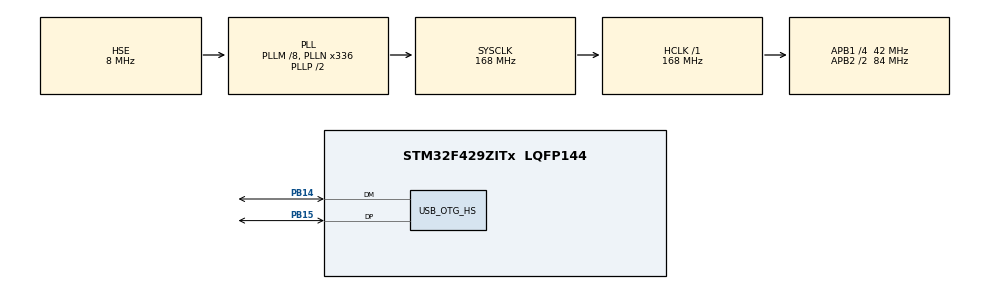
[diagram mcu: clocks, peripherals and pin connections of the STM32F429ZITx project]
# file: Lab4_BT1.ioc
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Mcu.Family=STM32F4
Mcu.Name=STM32F429ZITx
Mcu.Package=LQFP144
NVIC.OTG_HS_IRQn=true\:0\:0\:false\:false\:true\:true\:true\:true
NVIC.PriorityGroup=NVIC_PRIORITYGROUP_4
PA13.Mode=Serial_Wire
PA13.Signal=SYS_JTMS-SWDIO
PA14.Mode=Serial_Wire
PA14.Signal=SYS_JTCK-SWCLK
PB14.Mode=Device_Only_FS
PB14.Signal=USB_OTG_HS_DM
PB15.Mode=Device_Only_FS
PB15.Signal=USB_OTG_HS_DP
PH0/OSC_IN.Mode=HSE-External-Oscillator
PH0/OSC_IN.Signal=RCC_OSC_IN
PH1/OSC_OUT.Mode=HSE-External-Oscillator
PH1/OSC_OUT.Signal=RCC_OSC_OUT
ProjectManager.HeapSize=0x2000
ProjectManager.StackSize=0x400
ProjectManager.TargetToolchain=STM32CubeIDE
RCC.48MHZClocksFreq_Value=48000000
RCC.AHBFreq_Value=168000000
RCC.APB1CLKDivider=RCC_HCLK_DIV4
RCC.APB1Freq_Value=42000000
RCC.APB1TimFreq_Value=84000000
RCC.APB2CLKDivider=RCC_HCLK_DIV2
RCC.APB2Freq_Value=84000000
RCC.APB2TimFreq_Value=168000000
RCC.CortexFreq_Value=168000000
RCC.HCLKFreq_Value=168000000
RCC.HSE_VALUE=8000000
RCC.HSI_VALUE=16000000
RCC.LSE_VALUE=32768
RCC.PLLM=8
RCC.PLLN=336
RCC.PLLQ=7
RCC.SYSCLKFreq_VALUE=168000000
RCC.SYSCLKSource=RCC_SYSCLKSOURCE_PLLCLK
RCC.VCOOutputFreq_Value=336000000
USB_DEVICE.CLASS_NAME_HS=CDC
USB_DEVICE.VirtualMode-CDC_HS=Cdc
USB_DEVICE.VirtualModeHS=Cdc_HS
USB_OTG_HS.VirtualMode-Device_Only_FS=Device_Only_FS
VP_USB_DEVICE_VS_USB_DEVICE_CDC_HS.Mode=CDC_HS
board=custom

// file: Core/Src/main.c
/* USER CODE BEGIN Header */
/**
  ******************************************************************************
  * @file           : main.c
  * @brief          : Main program body
  ******************************************************************************
  * @attention
  *
  * Copyright (c) 2022 STMicroelectronics.
  * All rights reserved.
  *
  * This software is licensed under terms that can be found in the LICENSE file
  * in the root directory of this software component.
  * If no LICENSE file comes with this software, it is provided AS-IS.
  *
  ******************************************************************************
  */
/* USER CODE END Header */
#include "main.h"
#include "usb_device.h"
#include "usbd_cdc_if.h"
#include "stm32f429i_discovery_lcd.h"
#include "stm32f429i_discovery_gyroscope.h"

void SystemClock_Config(void);
static void MX_GPIO_Init(void);

int main(void)
{
  /* USER CODE BEGIN 1 */
	float DATA[3];
	char X[10], Y[10], Z[10];
  /* USER CODE END 1 */

  /* MCU Configuration--------------------------------------------------------*/

  /* Reset of all peripherals, Initializes the Flash interface and the Systick. */
  HAL_Init();

  /* Configure the system clock */
  SystemClock_Config();

  /* Initialize all configured peripherals */
  BSP_GYRO_Init();
  BSP_SDRAM_Init();
  MX_GPIO_Init();
  MX_USB_DEVICE_Init();
    /* USER CODE BEGIN 2 */
  BSP_LCD_Init();//init LCD
    //set the layer buffer address into SDRAM
  BSP_LCD_LayerDefaultInit(1, SDRAM_DEVICE_ADDR);
  BSP_LCD_SelectLayer(1);//select on which layer we write
  BSP_LCD_DisplayOn();//turn on LCD
  BSP_LCD_Clear(LCD_COLOR_BLUE);//clear the LCD on blue color
  BSP_LCD_SetBackColor(LCD_COLOR_BLUE);//set text background color
  BSP_LCD_SetTextColor(LCD_COLOR_WHITE);//set text color
    //write text
  /* USER CODE BEGIN 2 */

  /* USER CODE END 2 */

  /* Infinite loop */
  while (1)
  {
	  L3GD20_ReadXYZAngRate(&DATA);

	  if (DATA[0] < -10){
		  BSP_LCD_DisplayStringAtLine(0, (uint8_t*)"       ^");
	  	  BSP_LCD_DisplayStringAtLine(10, (uint8_t*)"        ");
	  }
	  else if (DATA[0] > 10){
		  BSP_LCD_DisplayStringAtLine(10, (uint8_t*)"       v");
	  	  BSP_LCD_DisplayStringAtLine(0, (uint8_t*)"        ");
	  }
	  else{
		  BSP_LCD_DisplayStringAtLine(0, (uint8_t*)"        ");
		  BSP_LCD_DisplayStringAtLine(10, (uint8_t*)"        ");
	  }

	  if (DATA[1] > 10)
		  BSP_LCD_DisplayStringAtLine(5, (uint8_t*)"             >");
	  else if (DATA[1] < -10)
		  BSP_LCD_DisplayStringAtLine(5, (uint8_t*)"<");
	  else
		  BSP_LCD_DisplayStringAtLine(5, (uint8_t*)"              ");

	  sprintf(X, "%f", DATA[0]);
	  sprintf(Y, "%f", DATA[1]);
	  sprintf(Z, "%f", DATA[2]);

	  CDC_Transmit_HS((uint8_t*)"\n XYZ: ", 8);
	  HAL_Delay(50);
	  CDC_Transmit_HS((uint8_t*)X, 10);
	  HAL_Delay(50);
	  CDC_Transmit_HS((uint8_t*)" ", 1);
	  HAL_Delay(50);
	  CDC_Transmit_HS((uint8_t*)Y, 10);
	  HAL_Delay(50);
	  CDC_Transmit_HS((uint8_t*)" ", 1);
	  HAL_Delay(50);
	  CDC_Transmit_HS((uint8_t*)Z, 10);
	  HAL_Delay(50);
	  CDC_Transmit_HS((uint8_t*)" ", 1);

	  HAL_Delay(200);
  }
}

/*BSP_LCD_DisplayStringAtLine(0, (uint8_t*)"Gyroscope: ");
	  BSP_LCD_DisplayStringAtLine(1, (uint8_t*)" X: ");
	  BSP_LCD_DisplayStringAtLine(2, (uint8_t*)X);
	  BSP_LCD_DisplayStringAtLine(3, (uint8_t*)" Y:");
	  BSP_LCD_DisplayStringAtLine(4, (uint8_t*)Y);
	  BSP_LCD_DisplayStringAtLine(5, (uint8_t*)" Z: ");
	  BSP_LCD_DisplayStringAtLine(6, (uint8_t*)Z);*/
void SystemClock_Config(void)
{
  RCC_OscInitTypeDef RCC_OscInitStruct = {0};
  RCC_ClkInitTypeDef RCC_ClkInitStruct = {0};

  /** Configure the main internal regulator output voltage
  */
  __HAL_RCC_PWR_CLK_ENABLE();
  __HAL_PWR_VOLTAGESCALING_CONFIG(PWR_REGULATOR_VOLTAGE_SCALE1);

  /** Initializes the RCC Oscillators according to the specified parameters
  * in the RCC_OscInitTypeDef structure.
  */
  RCC_OscInitStruct.OscillatorType = RCC_OSCILLATORTYPE_HSE;
  RCC_OscInitStruct.HSEState = RCC_HSE_ON;
  RCC_OscInitStruct.PLL.PLLState = RCC_PLL_ON;
  RCC_OscInitStruct.PLL.PLLSource = RCC_PLLSOURCE_HSE;
  RCC_OscInitStruct.PLL.PLLM = 8;
  RCC_OscInitStruct.PLL.PLLN = 336;
  RCC_OscInitStruct.PLL.PLLP = RCC_PLLP_DIV2;
  RCC_OscInitStruct.PLL.PLLQ = 7;
  if (HAL_RCC_OscConfig(&RCC_OscInitStruct) != HAL_OK)
  {
    Error_Handler();
  }

  /** Initializes the CPU, AHB and APB buses clocks
  */
  RCC_ClkInitStruct.ClockType = RCC_CLOCKTYPE_HCLK|RCC_CLOCKTYPE_SYSCLK
                              |RCC_CLOCKTYPE_PCLK1|RCC_CLOCKTYPE_PCLK2;
  RCC_ClkInitStruct.SYSCLKSource = RCC_SYSCLKSOURCE_PLLCLK;
  RCC_ClkInitStruct.AHBCLKDivider = RCC_SYSCLK_DIV1;
  RCC_ClkInitStruct.APB1CLKDivider = RCC_HCLK_DIV4;
  RCC_ClkInitStruct.APB2CLKDivider = RCC_HCLK_DIV2;

  if (HAL_RCC_ClockConfig(&RCC_ClkInitStruct, FLASH_LATENCY_5) != HAL_OK)
  {
    Error_Handler();
  }
}

static void MX_GPIO_Init(void)
{

  /* GPIO Ports Clock Enable */
  __HAL_RCC_GPIOH_CLK_ENABLE();
  __HAL_RCC_GPIOB_CLK_ENABLE();
  __HAL_RCC_GPIOA_CLK_ENABLE();

}

void Error_Handler(void)
{
  __disable_irq();
  while (1)
  {
  }
}
